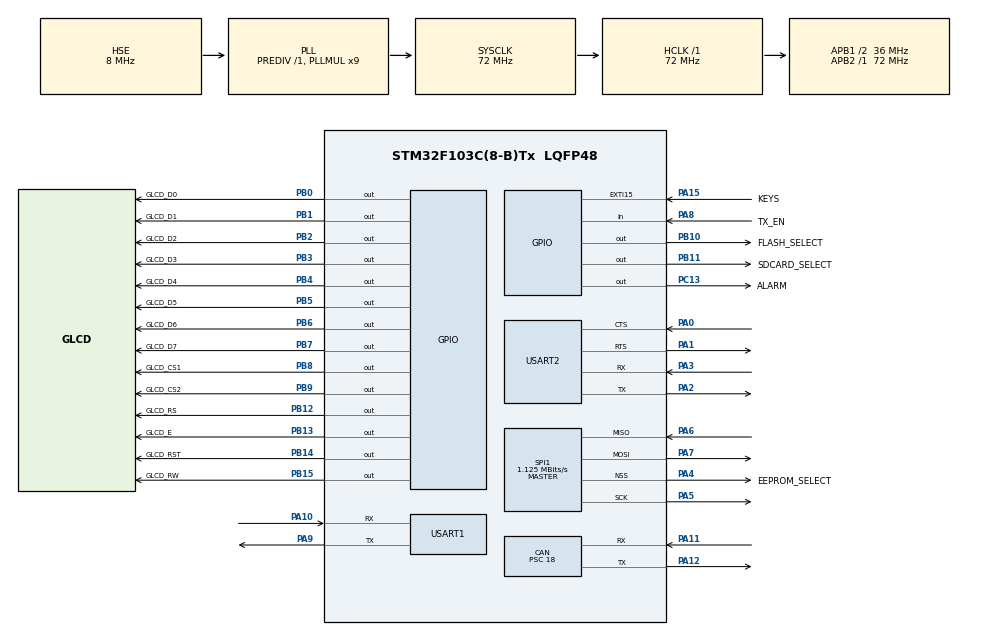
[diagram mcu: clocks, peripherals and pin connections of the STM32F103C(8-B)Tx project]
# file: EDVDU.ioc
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CAN.BS1=CAN_BS1_2TQ
CAN.CalculateBaudRate=500000
CAN.CalculateTimeBit=2000
CAN.CalculateTimeQuantum=500.0
CAN.Prescaler=18
FREERTOS.Tasks01=defaultTask,0,128,StartDefaultTask,Default,NULL,Dynamic,NULL,NULL
Mcu.Family=STM32F1
Mcu.Name=STM32F103C(8-B)Tx
Mcu.Package=LQFP48
NVIC.PriorityGroup=NVIC_PRIORITYGROUP_4
NVIC.TIM1_UP_IRQn=true\:15\:0\:false\:false\:true\:false\:false\:true\:true
NVIC.TimeBase=TIM1_UP_IRQn
NVIC.TimeBaseIP=TIM1
NVIC.USB_LP_CAN1_RX0_IRQn=true\:5\:0\:false\:false\:true\:true\:true\:true\:true
PA0-WKUP.Mode=CTS_RTS
PA0-WKUP.Signal=USART2_CTS
PA1.Mode=CTS_RTS
PA1.Signal=USART2_RTS
PA10.Mode=Asynchronous
PA10.Signal=USART1_RX
PA11.Mode=CAN_Activate
PA11.Signal=CAN_RX
PA12.Mode=CAN_Activate
PA12.Signal=CAN_TX
PA13.Mode=Serial_Wire
PA13.Signal=SYS_JTMS-SWDIO
PA14.Mode=Serial_Wire
PA14.Signal=SYS_JTCK-SWCLK
PA15.GPIO_Label=KEYS
PA15.Signal=GPXTI15
PA2.Mode=Asynchronous
PA2.Signal=USART2_TX
PA3.Mode=Asynchronous
PA3.Signal=USART2_RX
PA4.GPIO_Label=EEPROM_SELECT
PA4.Mode=NSS_Signal_Hard_Output
PA4.Signal=SPI1_NSS
PA5.Mode=Full_Duplex_Master
PA5.Signal=SPI1_SCK
PA6.Mode=Full_Duplex_Master
PA6.Signal=SPI1_MISO
PA7.Mode=Full_Duplex_Master
PA7.Signal=SPI1_MOSI
PA8.GPIO_Label=TX_EN
PA8.Signal=GPIO_Input
PA9.Mode=Asynchronous
PA9.Signal=USART1_TX
PB0.GPIO_Label=GLCD_D0
PB0.Signal=GPIO_Output
PB1.GPIO_Label=GLCD_D1
PB1.Signal=GPIO_Output
PB10.GPIO_Label=FLASH_SELECT
PB10.Signal=GPIO_Output
PB11.GPIO_Label=SDCARD_SELECT
PB11.Signal=GPIO_Output
PB12.GPIO_Label=GLCD_RS
PB12.Signal=GPIO_Output
PB13.GPIO_Label=GLCD_E
PB13.Signal=GPIO_Output
PB14.GPIO_Label=GLCD_RST
PB14.Signal=GPIO_Output
PB15.GPIO_Label=GLCD_RW
PB15.Signal=GPIO_Output
PB2.GPIO_Label=GLCD_D2
PB2.Signal=GPIO_Output
PB3.GPIO_Label=GLCD_D3
PB3.Signal=GPIO_Output
PB4.GPIO_Label=GLCD_D4
PB4.Signal=GPIO_Output
PB5.GPIO_Label=GLCD_D5
PB5.Signal=GPIO_Output
PB6.GPIO_Label=GLCD_D6
PB6.Signal=GPIO_Output
PB7.GPIO_Label=GLCD_D7
PB7.Signal=GPIO_Output
PB8.GPIO_Label=GLCD_CS1
PB8.Signal=GPIO_Output
PB9.GPIO_Label=GLCD_CS2
PB9.Signal=GPIO_Output
PC13-TAMPER-RTC.GPIO_Label=ALARM
PC13-TAMPER-RTC.Signal=GPIO_Output
PC14-OSC32_IN.Mode=LSE-External-Oscillator
PC14-OSC32_IN.Signal=RCC_OSC32_IN
PC15-OSC32_OUT.Mode=LSE-External-Oscillator
PC15-OSC32_OUT.Signal=RCC_OSC32_OUT
PD0-OSC_IN.Mode=HSE-External-Oscillator
PD0-OSC_IN.Signal=RCC_OSC_IN
PD1-OSC_OUT.Mode=HSE-External-Oscillator
PD1-OSC_OUT.Signal=RCC_OSC_OUT
ProjectManager.HeapSize=0x200
ProjectManager.StackSize=0x400
ProjectManager.TargetToolchain=MDK-ARM V5.32
RCC.ADCPresc=RCC_ADCPCLK2_DIV6
RCC.AHBFreq_Value=72000000
RCC.APB1CLKDivider=RCC_HCLK_DIV2
RCC.APB1Freq_Value=36000000
RCC.APB1TimFreq_Value=72000000
RCC.APB2Freq_Value=72000000
RCC.APB2TimFreq_Value=72000000
RCC.HCLKFreq_Value=72000000
RCC.PLLMUL=RCC_PLL_MUL9
RCC.PLLSourceVirtual=RCC_PLLSOURCE_HSE
RCC.RTCClockSelection=RCC_RTCCLKSOURCE_LSE
RCC.SYSCLKFreq_VALUE=72000000
RCC.SYSCLKSource=RCC_SYSCLKSOURCE_PLLCLK
RCC.USBFreq_Value=48000000
RCC.USBPrescaler=RCC_USBCLKSOURCE_PLL_DIV1_5
SPI1.BaudRatePrescaler=SPI_BAUDRATEPRESCALER_64
SPI1.CalculateBaudRate=1.125 MBits/s
SPI1.Direction=SPI_DIRECTION_2LINES
SPI1.Mode=SPI_MODE_MASTER
SPI1.VirtualNSS=VM_NSSHARD
SPI1.VirtualType=VM_MASTER
USART1.VirtualMode=VM_ASYNC
USART2.VirtualMode=VM_ASYNC
VP_FREERTOS_VS_CMSIS_V1.Mode=CMSIS_V1
VP_SYS_VS_tim1.Mode=TIM1
board=custom

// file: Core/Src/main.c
/* USER CODE BEGIN Header */
/**
  ******************************************************************************
  * @file           : main.c
  * @brief          : Main program body
  ******************************************************************************
  * @attention
  *
  * Copyright (c) 2022 STMicroelectronics.
  * All rights reserved.
  *
  * This software is licensed under terms that can be found in the LICENSE file
  * in the root directory of this software component.
  * If no LICENSE file comes with this software, it is provided AS-IS.
  *
  ******************************************************************************
  */
/* USER CODE END Header */
#include "main.h"
#include "cmsis_os.h"
#include "can.h"
#include "spi.h"
#include "usart.h"
#include "gpio.h"

void SystemClock_Config(void);
void MX_FREERTOS_Init(void);

int main(void)
{

  /* MCU Configuration--------------------------------------------------------*/

  /* Reset of all peripherals, Initializes the Flash interface and the Systick. */
  HAL_Init();

  /* Configure the system clock */
  SystemClock_Config();

  /* Initialize all configured peripherals */
  MX_GPIO_Init();
  MX_USART2_UART_Init();
  MX_USART1_UART_Init();
  MX_SPI1_Init();
  MX_CAN_Init();

  /* Call init function for freertos objects (in freertos.c) */
  MX_FREERTOS_Init();

  /* Start scheduler */
  osKernelStart();

  /* We should never get here as control is now taken by the scheduler */
  /* Infinite loop */
  while (1)
  {

  }
}

void SystemClock_Config(void)
{
  RCC_OscInitTypeDef RCC_OscInitStruct = {0};
  RCC_ClkInitTypeDef RCC_ClkInitStruct = {0};

  /** Initializes the RCC Oscillators according to the specified parameters
  * in the RCC_OscInitTypeDef structure.
  */
  RCC_OscInitStruct.OscillatorType = RCC_OSCILLATORTYPE_HSE;
  RCC_OscInitStruct.HSEState = RCC_HSE_ON;
  RCC_OscInitStruct.HSEPredivValue = RCC_HSE_PREDIV_DIV1;
  RCC_OscInitStruct.HSIState = RCC_HSI_ON;
  RCC_OscInitStruct.PLL.PLLState = RCC_PLL_ON;
  RCC_OscInitStruct.PLL.PLLSource = RCC_PLLSOURCE_HSE;
  RCC_OscInitStruct.PLL.PLLMUL = RCC_PLL_MUL9;
  if (HAL_RCC_OscConfig(&RCC_OscInitStruct) != HAL_OK)
  {
    Error_Handler();
  }

  /** Initializes the CPU, AHB and APB buses clocks
  */
  RCC_ClkInitStruct.ClockType = RCC_CLOCKTYPE_HCLK|RCC_CLOCKTYPE_SYSCLK
                              |RCC_CLOCKTYPE_PCLK1|RCC_CLOCKTYPE_PCLK2;
  RCC_ClkInitStruct.SYSCLKSource = RCC_SYSCLKSOURCE_PLLCLK;
  RCC_ClkInitStruct.AHBCLKDivider = RCC_SYSCLK_DIV1;
  RCC_ClkInitStruct.APB1CLKDivider = RCC_HCLK_DIV2;
  RCC_ClkInitStruct.APB2CLKDivider = RCC_HCLK_DIV1;

  if (HAL_RCC_ClockConfig(&RCC_ClkInitStruct, FLASH_LATENCY_2) != HAL_OK)
  {
    Error_Handler();
  }
}

void HAL_TIM_PeriodElapsedCallback(TIM_HandleTypeDef *htim)
{
  if (htim->Instance == TIM1) {
    HAL_IncTick();
  }
}

void Error_Handler(void)
{
  __disable_irq();
  while (1)
  {
  }
}

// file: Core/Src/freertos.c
/* USER CODE BEGIN Header */
/**
  ******************************************************************************
  * File Name          : freertos.c
  * Description        : Code for freertos applications
  ******************************************************************************
  * @attention
  *
  * Copyright (c) 2022 STMicroelectronics.
  * All rights reserved.
  *
  * This software is licensed under terms that can be found in the LICENSE file
  * in the root directory of this software component.
  * If no LICENSE file comes with this software, it is provided AS-IS.
  *
  ******************************************************************************
  */
/* USER CODE END Header */

#include "FreeRTOS.h"
#include "task.h"
#include "main.h"
#include "cmsis_os.h"

osThreadId defaultTaskHandle;

void StartDefaultTask(void const * argument);

void MX_FREERTOS_Init(void); /* (MISRA C 2004 rule 8.1) */

/* GetIdleTaskMemory prototype (linked to static allocation support) */
void vApplicationGetIdleTaskMemory( StaticTask_t **ppxIdleTaskTCBBuffer, StackType_t **ppxIdleTaskStackBuffer, uint32_t *pulIdleTaskStackSize );

/* USER CODE BEGIN GET_IDLE_TASK_MEMORY */
static StaticTask_t xIdleTaskTCBBuffer;
static StackType_t xIdleStack[configMINIMAL_STACK_SIZE];

void vApplicationGetIdleTaskMemory( StaticTask_t **ppxIdleTaskTCBBuffer, StackType_t **ppxIdleTaskStackBuffer, uint32_t *pulIdleTaskStackSize )
{
  *ppxIdleTaskTCBBuffer = &xIdleTaskTCBBuffer;
  *ppxIdleTaskStackBuffer = &xIdleStack[0];
  *pulIdleTaskStackSize = configMINIMAL_STACK_SIZE;
  /* place for user code */
}
/* USER CODE END GET_IDLE_TASK_MEMORY */

void MX_FREERTOS_Init(void) {

  /* Create the thread(s) */
  /* definition and creation of defaultTask */
  osThreadDef(defaultTask, StartDefaultTask, osPriorityNormal, 0, 128);
  defaultTaskHandle = osThreadCreate(osThread(defaultTask), NULL);

}

void StartDefaultTask(void const * argument)
{
  /* USER CODE BEGIN StartDefaultTask */
  /* Infinite loop */
  for(;;)
  {
		HAL_GPIO_TogglePin(ALARM_GPIO_Port, ALARM_Pin);
    osDelay(100);
  }
  /* USER CODE END StartDefaultTask */
}
